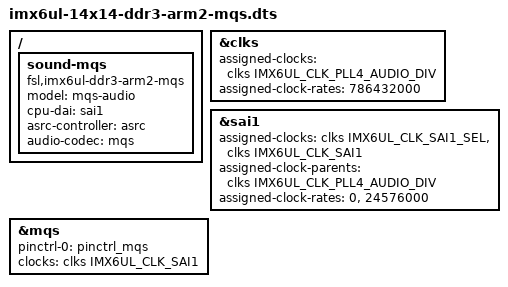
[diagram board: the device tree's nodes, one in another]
/*
 * Copyright (C) 2015 Freescale Semiconductor, Inc.
 *
 * This program is free software; you can redistribute it and/or modify
 * it under the terms of the GNU General Public License version 2 as
 * published by the Free Software Foundation.
 */

#include "imx6ul-14x14-ddr3-arm2.dts"

/ {
	sound-mqs {
		compatible = "fsl,imx6ul-ddr3-arm2-mqs",
				"fsl,imx-audio-mqs";
		model = "mqs-audio";
		cpu-dai = <&sai1>;
		asrc-controller = <&asrc>;
		audio-codec = <&mqs>;
	};
};

&clks {
	assigned-clocks = <&clks IMX6UL_CLK_PLL4_AUDIO_DIV>;
	assigned-clock-rates = <786432000>;
};

&sai1 {
	assigned-clocks = <&clks IMX6UL_CLK_SAI1_SEL>,
			<&clks IMX6UL_CLK_SAI1>;
	assigned-clock-parents = <&clks IMX6UL_CLK_PLL4_AUDIO_DIV>;
	assigned-clock-rates = <0>, <24576000>;
	status = "okay";
};

&mqs {
	pinctrl-names = "default";
	pinctrl-0 = <&pinctrl_mqs>;
	clocks = <&clks IMX6UL_CLK_SAI1>;
	clock-names = "mclk";
	status = "okay";
};
